# nrf9160_modem register map
Vendor: Nordic Semiconductor; Series: nrf91; File version: 1
CPU: CM4 r0p1, little endian, MPU, FPU, 3 interrupt priority bits
Registers are 32-bit, read-write, reset 0x0 unless marked. A register's access mark holds for its fields unless they carry their own. Offsets are from the block's base; [hi:lo] are bit positions; lines under a group give offsets from that group; {n}, {i} and the like mark numbered series; 'fields as' and 'values as' point back to an identical list.

## POWER_NS — Power Control
Base 0x40015000; alternate view of CLOCK_NS
0x60 TASKS_RFFELDOREQSTART wo — Start requesting RF Front-End 1V8 LDO (RFFELDO)
  [0] TASKS_RFFELDOREQSTART
    1=Trigger task
0x64 TASKS_RFFELDOREQSTOP wo — Stop requesting RF Front-End 1V8 LDO (RFFELDO)
  [0] TASKS_RFFELDOREQSTOP
    1=Trigger task
0x68 TASKS_IOIFLDOREQSTART wo — Start requesting IO interface 1V8 LDO (RFFELDO)
  [0] TASKS_IOIFLDOREQSTART
    1=Trigger task
0x6C TASKS_IOIFLDOREQSTOP wo — Stop requesting IO interface 1V8 LDO (RFFELDO)
  [0] TASKS_IOIFLDOREQSTOP
    1=Trigger task
0x70 TASKS_PWMREQSTART wo — Request forcing PWM mode in external DCDC voltage regulator
  [0] TASKS_PWMREQSTART
    1=Trigger task
0x74 TASKS_PWMREQSTOP wo — Stop requesting forcing PWM mode in external DCDC voltage regulator
  [0] TASKS_PWMREQSTOP
    1=Trigger task
0x78 TASKS_CONSTLAT wo — Enable constant latency mode. When going to sleep: CPU is clock gated, but regulators, oscillators and clock tree is kept on.
  [0] TASKS_CONSTLAT
    1=Trigger task
0x7C TASKS_LOWPWR wo — Enable low power mode (variable latency) When going to sleep: Oscillators are switched off (if nothing else is requesting clocks). Regulators are switched off (if nothing else is requesting power).
  [0] TASKS_LOWPWR
    1=Trigger task
0x108 EVENTS_POFWARN — Power failure warning
  [0] EVENTS_POFWARN
    0=NotGenerated (Event not generated); 1=Generated (Event generated)
0x10C EVENTS_RFFELDOSTARTED — RF Front-End 1V8 LDO (RFFELDO) has become ready
  [0] EVENTS_RFFELDOSTARTED
    values as EVENTS_POFWARN.EVENTS_POFWARN
0x110 EVENTS_IOIFLDOSTARED — IO interface 1V8 LDO (IOIFLDO) has become ready
  [0] EVENTS_IOIFLDOSTARED
    values as EVENTS_POFWARN.EVENTS_POFWARN
0x114 EVENTS_SLEEPENTER — CPU entered WFI/WFE sleep
  [0] EVENTS_SLEEPENTER
    values as EVENTS_POFWARN.EVENTS_POFWARN
0x118 EVENTS_SLEEPEXIT — CPU exited WFI/WFE sleep
  [0] EVENTS_SLEEPEXIT
    values as EVENTS_POFWARN.EVENTS_POFWARN
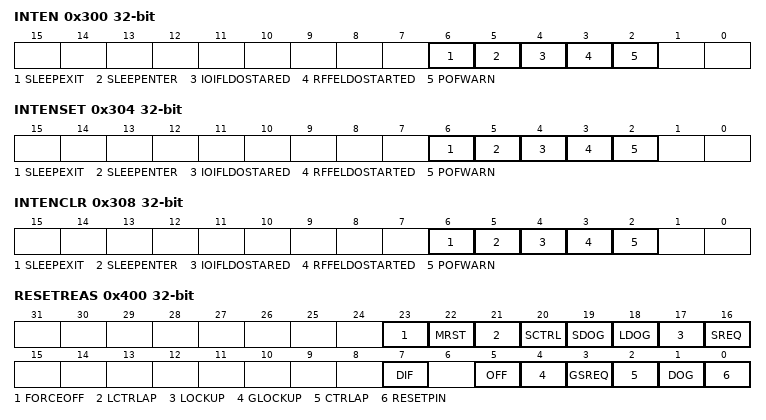
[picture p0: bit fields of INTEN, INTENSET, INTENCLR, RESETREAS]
0x300 INTEN — Enable or disable interrupt
  [all] fields
    0=Disabled; 1=Enabled
  [6] SLEEPEXIT — Enable or disable interrupt for event SLEEPEXIT
  [5] SLEEPENTER — Enable or disable interrupt for event SLEEPENTER
  [4] IOIFLDOSTARED — Enable or disable interrupt for event IOIFLDOSTARED
  [3] RFFELDOSTARTED — Enable or disable interrupt for event RFFELDOSTARTED
  [2] POFWARN — Enable or disable interrupt for event POFWARN
0x304 INTENSET — Enable interrupt
  [all] fields
    on read: 0=Disabled (Read: Disabled); 1=Enabled (Read: Enabled) | on write: 1=Set (Enable)
  [6] SLEEPEXIT — Write '1' to enable interrupt for event SLEEPEXIT
  [5] SLEEPENTER — Write '1' to enable interrupt for event SLEEPENTER
  [4] IOIFLDOSTARED — Write '1' to enable interrupt for event IOIFLDOSTARED
  [3] RFFELDOSTARTED — Write '1' to enable interrupt for event RFFELDOSTARTED
  [2] POFWARN — Write '1' to enable interrupt for event POFWARN
0x308 INTENCLR — Disable interrupt
  [all] fields
    on read: 0=Disabled (Read: Disabled); 1=Enabled (Read: Enabled) | on write: 1=Clear (Disable)
  [6] SLEEPEXIT — Write '1' to disable interrupt for event SLEEPEXIT
  [5] SLEEPENTER — Write '1' to disable interrupt for event SLEEPENTER
  [4] IOIFLDOSTARED — Write '1' to disable interrupt for event IOIFLDOSTARED
  [3] RFFELDOSTARTED — Write '1' to disable interrupt for event RFFELDOSTARTED
  [2] POFWARN — Write '1' to disable interrupt for event POFWARN
0x400 RESETREAS — Reset reason
  [all] fields
    0=NotDetected; 1=Detected
  [23] FORCEOFF — Force off reset from MCUMASTER detected
  [22] MRST — CPU reset from MCUMASTER detected
  [21] LCTRLAP — SW reset from modem CTRL-AP detected
  [20] SCTRL — Reset from secure control detected
  [19] SDOG — Reset from secure watchdog detected
  [18] LDOG — Reset from local watchdog detected
  [17] LOCKUP — Reset from local CPU lock-up detected
  [16] SREQ — Reset from local AIRCR.SYSRESETREQ detected
  [7] DIF — Reset due to wake up from System OFF mode when wakeup is triggered from entering into debug interface mode
  [5] OFF — Reset due to wake up from System OFF mode when wakeup is triggered from DETECT signal from GPIO
  [4] GLOCKUP — Reset from global application CPU lock-up detected
  [3] GSREQ — Reset from global application AIRCR.SYSRESETREQ detected
  [2] CTRLAP — Reset from global application CTRL-AP detected
  [1] DOG — Reset from global application watchdog detected
  [0] RESETPIN — Reset from pin-reset detected
0x440 DSPPOWERSTATUS ro reset 0x1 — Slave power status: DSP power domain power state.
  [0] DSPPOWERSTATUS — Modem DSP power state
    0=ON (DSP domain powered on); 1=OFF (DSP domain powered off)
0x444 M0POWERSTATUS ro reset 0x1 — Slave power status: RF M0 power domain power state.
  [0] M0POWERSTATUS — Modem RF M0 power state
    0=ON (RF domain powered on); 1=OFF (RF domain powered off)
0x510 SLEEPCNF — Sleep configuration
  [0] SLEEPMODE
    0=LIGHTSLEEP (Light sleep FF retention mode will be used if available. Otherwise FFs are kept powered.); 1=DEEPSLEEP (Deep sleep (wake from reset) No FF retention (needs wake from reset).)
{0x51C+4i} GPREGRET[{i}] (i=0..1) — Description collection: General purpose retention register
  [7:0] GPREGRET — General purpose retention register
0x610 DSP group — Control register for DSP
  0x00 RESET reset 0x1 — Reset DSP subsystem
    [0] RESET
      0=Release CPU reset signal; 1=Hold CPU reset signal
  0x08 FORCEON — Force on power and clock in DSP subsystem
    [0] FORCEON — Forces on power and clock in DSP subsystem
      0=Release force on signal; 1=Hold force on signal
  0x0C HALT reset 0x1 — Halt DSP subsystem
    [0] HALT
      0=Release halt signal; 1=Hold halt signal
0x620 LYNX group — Control register for Lynx RF subsystem
  0x00 RESET reset 0x1 — Reset Lynx RF subsystem
    [0] RESET — CPU soft reset
      0=Release CPU reset signal; 1=Hold CPU reset signal
  0x08 FORCEON — Force on Lynx RF subsystem
    [0] FORCEON — Forces an power and clock DSP subsystem
      0=Release force on signal; 1=Hold force on signal
